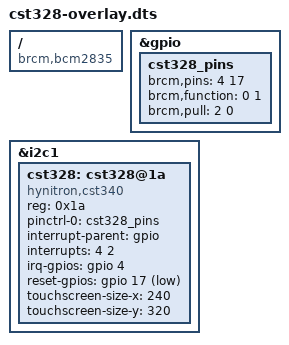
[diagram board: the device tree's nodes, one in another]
// SPDX-License-Identifier: GPL-2.0 OR MIT
/*
 * Device Tree overlay for the Hynitron CST328 capacitive touch controller
 * as fitted to the Waveshare 2.8 inch Capacitive Touch LCD, SKU 27579.
 *
 * Licensed GPL-2.0 OR MIT rather than the repository's Apache-2.0, following
 * the upstream convention for device tree sources. Apache-2.0 is not
 * GPL-2.0 compatible, and this dual licence keeps the overlay eligible for
 * submission to the Raspberry Pi kernel tree.
 *
 * Panel is 240(H) x 320(V) native portrait. The ST7789V display side is
 * handled separately (fbtft, panel-mipi-dbi, or the userspace renderer in
 * this repository); this overlay covers touch only.
 *
 * Default wiring per the Waveshare wiki, BCM numbering:
 *   TP_SDA  GPIO2   (i2c1)
 *   TP_SCL  GPIO3   (i2c1)
 *   TP_INT  GPIO4
 *   TP_RST  GPIO17
 *
 * Binding note: the in-tree driver (drivers/input/touchscreen/hynitron_cstxxx.c)
 * declares only "hynitron,cst340". The CST328 datasheet documents the same
 * register map the driver uses, including the 0xCACA firmware verification
 * code at 0xD1FC that the driver tests at probe. Binding to cst340 is
 * therefore expected to work. Unverified on silicon at time of writing.
 *
 * RSTn has a built-in pull-up and RC filter on the CST328 (datasheet 10.5),
 * so no external pull is configured on that pin.
 */

/dts-v1/;
/plugin/;

/ {
	compatible = "brcm,bcm2835";

	fragment@0 {
		target = <&gpio>;
		__overlay__ {
			cst328_pins: cst328_pins {
				brcm,pins = <4 17>;
				brcm,function = <0 1>;	/* in, out */
				brcm,pull = <2 0>;	/* pullup, none */
			};
		};
	};

	fragment@1 {
		target = <&i2c1>;
		__overlay__ {
			#address-cells = <1>;
			#size-cells = <0>;
			status = "okay";

			cst328: cst328@1a {
				compatible = "hynitron,cst340";
				reg = <0x1a>;
				pinctrl-names = "default";
				pinctrl-0 = <&cst328_pins>;
				interrupt-parent = <&gpio>;
				interrupts = <4 2>;	/* falling edge */
				irq-gpios = <&gpio 4 0>;
				reset-gpios = <&gpio 17 1>;	/* active low */
				touchscreen-size-x = <240>;
				touchscreen-size-y = <320>;
				status = "okay";
			};
		};
	};

	/* Dormant fragments, enabled via the overrides below. */

	fragment@2 {
		target = <&cst328>;
		__dormant__ {
			touchscreen-inverted-x;
		};
	};

	fragment@3 {
		target = <&cst328>;
		__dormant__ {
			touchscreen-inverted-y;
		};
	};

	fragment@4 {
		target = <&cst328>;
		__dormant__ {
			touchscreen-swapped-x-y;
		};
	};

	__overrides__ {
		addr    = <&cst328>,"reg:0";
		int_pin = <&cst328_pins>,"brcm,pins:0",
			  <&cst328>,"interrupts:0",
			  <&cst328>,"irq-gpios:4";
		rst_pin = <&cst328_pins>,"brcm,pins:4",
			  <&cst328>,"reset-gpios:4";
		sizex   = <&cst328>,"touchscreen-size-x:0";
		sizey   = <&cst328>,"touchscreen-size-y:0";
		invx    = <0>,"+2";
		invy    = <0>,"+3";
		swapxy  = <0>,"+4";
	};
};
